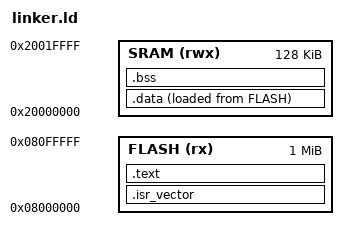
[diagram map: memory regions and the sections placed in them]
/* PM32F407 linker script (STM32F407-compatible) */
ENTRY(Reset_Handler)

MEMORY {
    FLASH (rx)  : ORIGIN = 0x08000000, LENGTH = 1M
    SRAM  (rwx) : ORIGIN = 0x20000000, LENGTH = 128K
}

_estack = ORIGIN(SRAM) + LENGTH(SRAM);  /* top of SRAM */

SECTIONS {
    .isr_vector : {
        KEEP(*(.isr_vector))
    } > FLASH

    .text : {
        *(.text*)
        *(.rodata*)
        . = ALIGN(4);
        _etext = .;
    } > FLASH

    _sidata = LOADADDR(.data);

    .data : {
        . = ALIGN(4);
        _sdata = .;
        *(.data*)
        . = ALIGN(4);
        _edata = .;
    } > SRAM AT> FLASH

    .bss : {
        . = ALIGN(4);
        _sbss = .;
        *(.bss*)
        *(COMMON)
        . = ALIGN(4);
        _ebss = .;
    } > SRAM
}
